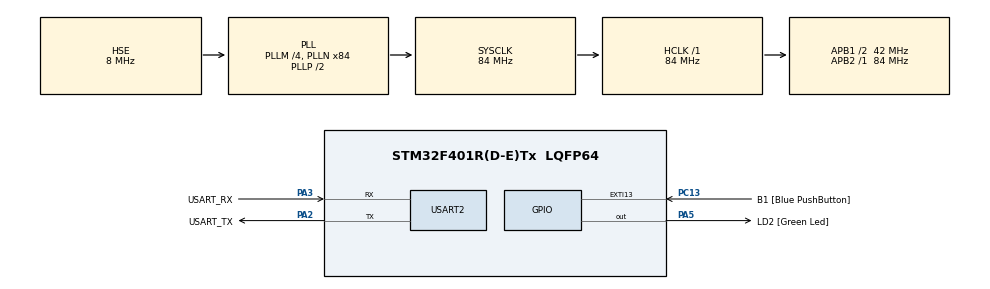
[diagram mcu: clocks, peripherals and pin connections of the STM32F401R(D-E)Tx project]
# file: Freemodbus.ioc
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Mcu.Family=STM32F4
Mcu.Name=STM32F401R(D-E)Tx
Mcu.Package=LQFP64
NVIC.PriorityGroup=NVIC_PRIORITYGROUP_2
NVIC.TIM4_IRQn=true\:2\:0\:true\:false\:false\:true\:true\:true
NVIC.USART2_IRQn=true\:1\:0\:true\:false\:false\:true\:true\:true
PA13.GPIO_Label=TMS
PA13.Mode=Serial_Wire
PA13.Signal=SYS_JTMS-SWDIO
PA14.GPIO_Label=TCK
PA14.Mode=Serial_Wire
PA14.Signal=SYS_JTCK-SWCLK
PA2.GPIO_Label=USART_TX
PA2.GPIO_Mode=GPIO_MODE_AF_PP
PA2.GPIO_PuPd=GPIO_NOPULL
PA2.GPIO_Speed=GPIO_SPEED_FREQ_LOW
PA2.Mode=Asynchronous
PA2.Signal=USART2_TX
PA3.GPIO_Label=USART_RX
PA3.GPIO_Mode=GPIO_MODE_AF_PP
PA3.GPIO_PuPd=GPIO_NOPULL
PA3.GPIO_Speed=GPIO_SPEED_FREQ_LOW
PA3.Mode=Asynchronous
PA3.Signal=USART2_RX
PA5.GPIO_Label=LD2 [Green Led]
PA5.GPIO_Mode=GPIO_MODE_OUTPUT_PP
PA5.GPIO_PuPd=GPIO_NOPULL
PA5.GPIO_Speed=GPIO_SPEED_FREQ_LOW
PA5.Signal=GPIO_Output
PB3.GPIO_Label=SWO
PB3.Signal=SYS_JTDO-SWO
PC13-ANTI_TAMP.GPIO_Label=B1 [Blue PushButton]
PC13-ANTI_TAMP.GPIO_ModeDefaultEXTI=GPIO_MODE_IT_FALLING
PC13-ANTI_TAMP.GPIO_PuPd=GPIO_NOPULL
PC13-ANTI_TAMP.Signal=GPXTI13
PC14-OSC32_IN.Mode=LSE-External-Oscillator
PC14-OSC32_IN.Signal=RCC_OSC32_IN
PC15-OSC32_OUT.Mode=LSE-External-Oscillator
PC15-OSC32_OUT.Signal=RCC_OSC32_OUT
PH0\ -\ OSC_IN.Mode=HSE-External-Clock-Source
PH0\ -\ OSC_IN.Signal=RCC_OSC_IN
PH1\ -\ OSC_OUT.Mode=HSE-External-Clock-Source
PH1\ -\ OSC_OUT.Signal=RCC_OSC_OUT
ProjectManager.HeapSize=0x200
ProjectManager.StackSize=0x400
ProjectManager.TargetToolchain=MDK-ARM V5.32
RCC.48MHZClocksFreq_Value=24000000
RCC.AHBFreq_Value=84000000
RCC.APB1CLKDivider=RCC_HCLK_DIV2
RCC.APB1Freq_Value=42000000
RCC.APB1TimFreq_Value=84000000
RCC.APB2Freq_Value=84000000
RCC.APB2TimFreq_Value=84000000
RCC.CortexFreq_Value=84000000
RCC.HCLKFreq_Value=84000000
RCC.HSE_VALUE=8000000
RCC.HSI_VALUE=16000000
RCC.PLLM=4
RCC.PLLN=84
RCC.PLLQ=7
RCC.PLLSourceVirtual=RCC_PLLSOURCE_HSE
RCC.SYSCLKFreq_VALUE=84000000
RCC.SYSCLKSource=RCC_SYSCLKSOURCE_PLLCLK
RCC.VCOOutputFreq_Value=168000000
TIM4.Period=1
TIM4.Prescaler=8399
USART2.VirtualMode=VM_ASYNC
VP_TIM4_VS_ClockSourceINT.Mode=Internal
board=NUCLEO-F401RE

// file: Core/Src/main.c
/* USER CODE BEGIN Header */
/**
  ******************************************************************************
  * @file           : main.c
  * @brief          : Main program body
  ******************************************************************************
  * @attention
  *
  * Copyright (c) 2022 STMicroelectronics.
  * All rights reserved.
  *
  * This software is licensed under terms that can be found in the LICENSE file
  * in the root directory of this software component.
  * If no LICENSE file comes with this software, it is provided AS-IS.
  *
  ******************************************************************************
  */
/* USER CODE END Header */
#include "main.h"
#include "tim.h"
#include "usart.h"
#include "gpio.h"

/* USER CODE BEGIN Includes */
#include "mb.h"
/* USER CODE END Includes */

void SystemClock_Config(void);

int main(void)
{

  /* MCU Configuration--------------------------------------------------------*/

  /* Reset of all peripherals, Initializes the Flash interface and the Systick. */
  HAL_Init();

  /* Configure the system clock */
  SystemClock_Config();

  /* Initialize all configured peripherals */
  MX_GPIO_Init();
  MX_TIM4_Init();
  MX_USART2_UART_Init();
  /* USER CODE BEGIN 2 */
  eMBInit(MB_RTU, 0x01, 0, 115200, MB_PAR_NONE);		// 初始化modbus为RTU方式，波特率9600，奇校验
  eMBEnable();
  /* USER CODE END 2 */

  /* Infinite loop */
  while (1)
  {

    /* USER CODE BEGIN 3 */
	  eMBPoll();
  }
  /* USER CODE END 3 */
}

void SystemClock_Config(void)
{
  RCC_OscInitTypeDef RCC_OscInitStruct = {0};
  RCC_ClkInitTypeDef RCC_ClkInitStruct = {0};

  /** Configure the main internal regulator output voltage
  */
  __HAL_RCC_PWR_CLK_ENABLE();
  __HAL_PWR_VOLTAGESCALING_CONFIG(PWR_REGULATOR_VOLTAGE_SCALE2);

  /** Initializes the RCC Oscillators according to the specified parameters
  * in the RCC_OscInitTypeDef structure.
  */
  RCC_OscInitStruct.OscillatorType = RCC_OSCILLATORTYPE_HSE;
  RCC_OscInitStruct.HSEState = RCC_HSE_BYPASS;
  RCC_OscInitStruct.PLL.PLLState = RCC_PLL_ON;
  RCC_OscInitStruct.PLL.PLLSource = RCC_PLLSOURCE_HSE;
  RCC_OscInitStruct.PLL.PLLM = 4;
  RCC_OscInitStruct.PLL.PLLN = 84;
  RCC_OscInitStruct.PLL.PLLP = RCC_PLLP_DIV2;
  RCC_OscInitStruct.PLL.PLLQ = 7;
  if (HAL_RCC_OscConfig(&RCC_OscInitStruct) != HAL_OK)
  {
    Error_Handler();
  }

  /** Initializes the CPU, AHB and APB buses clocks
  */
  RCC_ClkInitStruct.ClockType = RCC_CLOCKTYPE_HCLK|RCC_CLOCKTYPE_SYSCLK
                              |RCC_CLOCKTYPE_PCLK1|RCC_CLOCKTYPE_PCLK2;
  RCC_ClkInitStruct.SYSCLKSource = RCC_SYSCLKSOURCE_PLLCLK;
  RCC_ClkInitStruct.AHBCLKDivider = RCC_SYSCLK_DIV1;
  RCC_ClkInitStruct.APB1CLKDivider = RCC_HCLK_DIV2;
  RCC_ClkInitStruct.APB2CLKDivider = RCC_HCLK_DIV1;

  if (HAL_RCC_ClockConfig(&RCC_ClkInitStruct, FLASH_LATENCY_2) != HAL_OK)
  {
    Error_Handler();
  }
}

void Error_Handler(void)
{
  __disable_irq();
  while (1)
  {
  }
}
